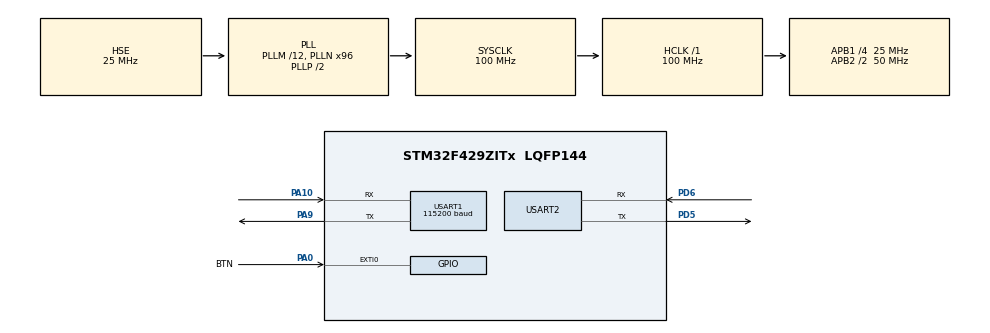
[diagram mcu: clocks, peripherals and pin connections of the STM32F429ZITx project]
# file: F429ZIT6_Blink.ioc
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Mcu.Family=STM32F4
Mcu.Name=STM32F429ZITx
Mcu.Package=LQFP144
NVIC.PriorityGroup=NVIC_PRIORITYGROUP_4
PA0/WKUP.GPIO_Label=BTN
PA0/WKUP.GPIO_ModeDefaultEXTI=GPIO_MODE_IT_RISING_FALLING
PA0/WKUP.GPIO_PuPd=GPIO_PULLUP
PA0/WKUP.Signal=GPXTI0
PA10.Mode=Asynchronous
PA10.Signal=USART1_RX
PA13.Mode=Trace_Asynchronous_SW
PA13.Signal=SYS_JTMS-SWDIO
PA14.Mode=Trace_Asynchronous_SW
PA14.Signal=SYS_JTCK-SWCLK
PA9.Mode=Asynchronous
PA9.Signal=USART1_TX
PB3.Mode=Trace_Asynchronous_SW
PB3.Signal=SYS_JTDO-SWO
PD5.Mode=Asynchronous
PD5.Signal=USART2_TX
PD6.Mode=Asynchronous
PD6.Signal=USART2_RX
PH0/OSC_IN.Mode=HSE-External-Oscillator
PH0/OSC_IN.Signal=RCC_OSC_IN
PH1/OSC_OUT.Mode=HSE-External-Oscillator
PH1/OSC_OUT.Signal=RCC_OSC_OUT
ProjectManager.HeapSize=0x200
ProjectManager.StackSize=0x400
ProjectManager.TargetToolchain=STM32CubeIDE
RCC.48MHZClocksFreq_Value=50000000
RCC.AHBFreq_Value=100000000
RCC.APB1CLKDivider=RCC_HCLK_DIV4
RCC.APB1Freq_Value=25000000
RCC.APB1TimFreq_Value=50000000
RCC.APB2CLKDivider=RCC_HCLK_DIV2
RCC.APB2Freq_Value=50000000
RCC.APB2TimFreq_Value=100000000
RCC.CortexFreq_Value=100000000
RCC.HCLKFreq_Value=100000000
RCC.HSE_VALUE=25000000
RCC.HSI_VALUE=16000000
RCC.LSE_VALUE=32768
RCC.PLLM=12
RCC.PLLN=96
RCC.PLLSourceVirtual=RCC_PLLSOURCE_HSE
RCC.SYSCLKFreq_VALUE=100000000
RCC.SYSCLKSource=RCC_SYSCLKSOURCE_PLLCLK
RCC.VCOOutputFreq_Value=200000000
USART1.BaudRate=115200
USART1.VirtualMode=VM_ASYNC
USART2.VirtualMode=VM_ASYNC
board=custom

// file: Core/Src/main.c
/* USER CODE BEGIN Header */
/**
  ******************************************************************************
  * @file           : main.c
  * @brief          : Main program body
  ******************************************************************************
  * @attention
  *
  * Copyright (c) 2025 STMicroelectronics.
  * All rights reserved.
  *
  * This software is licensed under terms that can be found in the LICENSE file
  * in the root directory of this software component.
  * If no LICENSE file comes with this software, it is provided AS-IS.
  *
  ******************************************************************************
  */
/* USER CODE END Header */
#include "main.h"

/* USER CODE BEGIN Includes */
#include <stdio.h>
/* USER CODE END Includes */

UART_HandleTypeDef huart1;
UART_HandleTypeDef huart2;

void SystemClock_Config(void);
static void MX_GPIO_Init(void);
static void MX_USART1_UART_Init(void);
static void MX_USART2_UART_Init(void);

/* USER CODE BEGIN 0 */
int _write(int fd, char* ptr, int len){
	HAL_StatusTypeDef hstatus;

	if (fd ==1 || fd == 2){
		hstatus = HAL_UART_Transmit(&huart2, (uint8_t *) ptr, len, HAL_MAX_DELAY);
		if(hstatus == HAL_OK){
			return len;
		}else{
			return -1;
		}
	}
	return -1;
}
/* USER CODE END 0 */

int main(void)
{

  /* MCU Configuration--------------------------------------------------------*/

  /* Reset of all peripherals, Initializes the Flash interface and the Systick. */
  HAL_Init();

  /* Configure the system clock */
  SystemClock_Config();

  /* Initialize all configured peripherals */
  MX_GPIO_Init();
  MX_USART1_UART_Init();
  MX_USART2_UART_Init();
  /* USER CODE BEGIN 2 */
  //printf("First application starting\n");
  //char message[] = "Testing USART2\n";
  //HAL_UART_Transmit(&huart2, (uint8_t *)message, sizeof(message)-1, HAL_MAX_DELAY);
  /* USER CODE END 2 */

  /* Infinite loop */
  while (1)
  {

    /* USER CODE BEGIN 3 */
	  printf("First application starting\n");
	  //HAL_UART_Transmit(&huart2, (uint8_t *)message, sizeof(message)-1, HAL_MAX_DELAY);
	  HAL_Delay(1000);
  }
  /* USER CODE END 3 */
}

void SystemClock_Config(void)
{
  RCC_OscInitTypeDef RCC_OscInitStruct = {0};
  RCC_ClkInitTypeDef RCC_ClkInitStruct = {0};

  /** Configure the main internal regulator output voltage
  */
  __HAL_RCC_PWR_CLK_ENABLE();
  __HAL_PWR_VOLTAGESCALING_CONFIG(PWR_REGULATOR_VOLTAGE_SCALE3);

  /** Initializes the RCC Oscillators according to the specified parameters
  * in the RCC_OscInitTypeDef structure.
  */
  RCC_OscInitStruct.OscillatorType = RCC_OSCILLATORTYPE_HSE;
  RCC_OscInitStruct.HSEState = RCC_HSE_ON;
  RCC_OscInitStruct.PLL.PLLState = RCC_PLL_ON;
  RCC_OscInitStruct.PLL.PLLSource = RCC_PLLSOURCE_HSE;
  RCC_OscInitStruct.PLL.PLLM = 12;
  RCC_OscInitStruct.PLL.PLLN = 96;
  RCC_OscInitStruct.PLL.PLLP = RCC_PLLP_DIV2;
  RCC_OscInitStruct.PLL.PLLQ = 4;
  if (HAL_RCC_OscConfig(&RCC_OscInitStruct) != HAL_OK)
  {
    Error_Handler();
  }

  /** Initializes the CPU, AHB and APB buses clocks
  */
  RCC_ClkInitStruct.ClockType = RCC_CLOCKTYPE_HCLK|RCC_CLOCKTYPE_SYSCLK
                              |RCC_CLOCKTYPE_PCLK1|RCC_CLOCKTYPE_PCLK2;
  RCC_ClkInitStruct.SYSCLKSource = RCC_SYSCLKSOURCE_PLLCLK;
  RCC_ClkInitStruct.AHBCLKDivider = RCC_SYSCLK_DIV1;
  RCC_ClkInitStruct.APB1CLKDivider = RCC_HCLK_DIV4;
  RCC_ClkInitStruct.APB2CLKDivider = RCC_HCLK_DIV2;

  if (HAL_RCC_ClockConfig(&RCC_ClkInitStruct, FLASH_LATENCY_3) != HAL_OK)
  {
    Error_Handler();
  }
}

static void MX_USART1_UART_Init(void)
{

  huart1.Instance = USART1;
  huart1.Init.BaudRate = 115200;
  huart1.Init.WordLength = UART_WORDLENGTH_8B;
  huart1.Init.StopBits = UART_STOPBITS_1;
  huart1.Init.Parity = UART_PARITY_NONE;
  huart1.Init.Mode = UART_MODE_TX_RX;
  huart1.Init.HwFlowCtl = UART_HWCONTROL_NONE;
  huart1.Init.OverSampling = UART_OVERSAMPLING_16;
  if (HAL_UART_Init(&huart1) != HAL_OK)
  {
    Error_Handler();
  }

}

static void MX_USART2_UART_Init(void)
{

  huart2.Instance = USART2;
  huart2.Init.BaudRate = 115200;
  huart2.Init.WordLength = UART_WORDLENGTH_8B;
  huart2.Init.StopBits = UART_STOPBITS_1;
  huart2.Init.Parity = UART_PARITY_NONE;
  huart2.Init.Mode = UART_MODE_TX_RX;
  huart2.Init.HwFlowCtl = UART_HWCONTROL_NONE;
  huart2.Init.OverSampling = UART_OVERSAMPLING_16;
  if (HAL_UART_Init(&huart2) != HAL_OK)
  {
    Error_Handler();
  }

}

static void MX_GPIO_Init(void)
{
  GPIO_InitTypeDef GPIO_InitStruct = {0};

  /* GPIO Ports Clock Enable */
  __HAL_RCC_GPIOH_CLK_ENABLE();
  __HAL_RCC_GPIOA_CLK_ENABLE();
  __HAL_RCC_GPIOD_CLK_ENABLE();
  __HAL_RCC_GPIOB_CLK_ENABLE();

  /*Configure GPIO pin : BTN_Pin */
  GPIO_InitStruct.Pin = BTN_Pin;
  GPIO_InitStruct.Mode = GPIO_MODE_IT_RISING_FALLING;
  GPIO_InitStruct.Pull = GPIO_PULLUP;
  HAL_GPIO_Init(BTN_GPIO_Port, &GPIO_InitStruct);

}

void Error_Handler(void)
{
  __disable_irq();
  while (1)
  {
  }
}
